# CY8C5888LTI_LP097 register map
File version: 0.1
Registers are 8-bit, read-write, no defined reset value unless marked. A register's access mark holds for its fields unless they carry their own. Offsets are from the block's base; [hi:lo] are bit positions; 'fields as' and 'values as' point back to an identical list.

## PWM_1
Base 0x00000000
0x40006524 PWM_1_COMPARE_Reg 16-bit — UDB.D0 - Assigned Compare Value
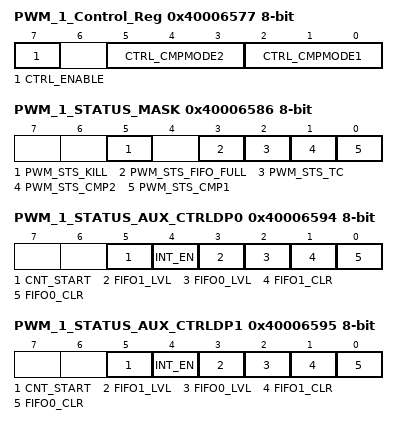
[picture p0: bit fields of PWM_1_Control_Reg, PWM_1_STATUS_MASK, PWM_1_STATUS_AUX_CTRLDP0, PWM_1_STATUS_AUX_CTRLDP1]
0x40006577 PWM_1_Control_Reg — UDB Control Register - Assigned Control Register Value
  [7] CTRL_ENABLE — Enable the PWM
  [5:3] CTRL_CMPMODE2 — Compare mode 2
  [2:0] CTRL_CMPMODE1 — Compare mode 1
0x40006586 PWM_1_STATUS_MASK — UDB Status bits Interrupt Mask Enable Register
  [5] PWM_STS_KILL ro — Enables the Interrupt on Kill
  [3] PWM_STS_FIFO_FULL ro — FIFO Full Status Mask
  [2] PWM_STS_TC ro — Enables the Interrupt on Terminal Count
  [1] PWM_STS_CMP2 ro — Enables the Interrupt on Compare 2
  [0] PWM_STS_CMP1 ro — Enables the Interrupt on Compare 1
0x40006594 PWM_1_STATUS_AUX_CTRLDP0 — UDB Auxilliary Control Register
  [5] CNT_START — FIFO0 clear
    0=E_CNT_START0 (Disable counter); 1=E_CNT_START1 (Enable counter)
  [4] INT_EN
    0=E_INT_EN0 (Interrupt disabled); 1=E_INT_EN1 (Interrupt enabled)
  [3] FIFO1_LVL — FIFO level
    0=E_FIFO_LVL_0 (FIFO LVL: input mode: FIFO not full; output mode: FIFO not empty); 1=E_FIFO_LVL_1 (FIFO LVL: input mode: FIFO at least 1/2 empty; output mode: FIFO at least 1/2 full)
  [2] FIFO0_LVL — FIFO level
    values as FIFO1_LVL
  [1] FIFO1_CLR — FIFO1 clear
    0=E_FIFO_CLR_0 (Normal FIFO operation); 1=E_FIFO_CLR_1 (Clear FIFO state)
  [0] FIFO0_CLR — FIFO0 clear
    values as FIFO1_CLR
0x40006595 PWM_1_STATUS_AUX_CTRLDP1 — UDB Auxilliary Control Register
  fields as PWM_1_STATUS_AUX_CTRLDP0

## Control_Reg_ServoSelect
Base 0x00000000
0x40006476 Control_Reg_ServoSelect_CONTROL_REG

## Control_Reg_ServoTrigger
Base 0x00000000
0x40006576 Control_Reg_ServoTrigger_CONTROL_REG

## Control_Reg_US
Base 0x00000000
0x40006579 Control_Reg_US_CONTROL_REG

## PWM_Trigger
Base 0x00000000
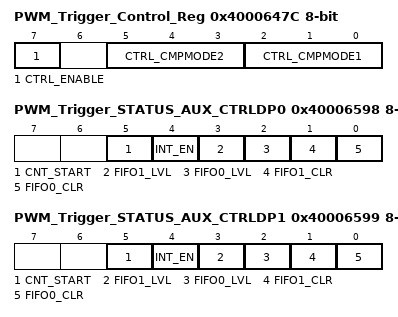
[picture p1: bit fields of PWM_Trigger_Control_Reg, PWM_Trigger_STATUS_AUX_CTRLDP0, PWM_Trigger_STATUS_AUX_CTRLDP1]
0x4000647C PWM_Trigger_Control_Reg — UDB Control Register - Assigned Control Register Value
  [7] CTRL_ENABLE — Enable the PWM
  [5:3] CTRL_CMPMODE2 — Compare mode 2
  [2:0] CTRL_CMPMODE1 — Compare mode 1
0x40006528 PWM_Trigger_COMPARE_Reg 16-bit — UDB.D0 - Assigned Compare Value
0x40006598 PWM_Trigger_STATUS_AUX_CTRLDP0 — UDB Auxilliary Control Register
  [5] CNT_START — FIFO0 clear
    0=E_CNT_START0 (Disable counter); 1=E_CNT_START1 (Enable counter)
  [4] INT_EN
    0=E_INT_EN0 (Interrupt disabled); 1=E_INT_EN1 (Interrupt enabled)
  [3] FIFO1_LVL — FIFO level
    0=E_FIFO_LVL_0 (FIFO LVL: input mode: FIFO not full; output mode: FIFO not empty); 1=E_FIFO_LVL_1 (FIFO LVL: input mode: FIFO at least 1/2 empty; output mode: FIFO at least 1/2 full)
  [2] FIFO0_LVL — FIFO level
    values as FIFO1_LVL
  [1] FIFO1_CLR — FIFO1 clear
    0=E_FIFO_CLR_0 (Normal FIFO operation); 1=E_FIFO_CLR_1 (Clear FIFO state)
  [0] FIFO0_CLR — FIFO0 clear
    values as FIFO1_CLR
0x40006599 PWM_Trigger_STATUS_AUX_CTRLDP1 — UDB Auxilliary Control Register
  fields as PWM_Trigger_STATUS_AUX_CTRLDP0

## UART
Base 0x00000000
0x40006444 TX_UART_TX_DATA — TX Data Register
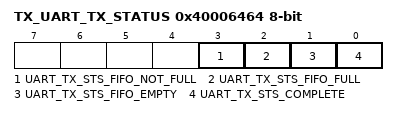
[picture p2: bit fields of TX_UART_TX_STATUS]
0x40006464 TX_UART_TX_STATUS — TX status register
  [3] UART_TX_STS_FIFO_NOT_FULL ro, [2] UART_TX_STS_FIFO_FULL ro, [1] UART_TX_STS_FIFO_EMPTY ro, [0] UART_TX_STS_COMPLETE ro

## Timer_Echo
Base 0x00000000
0x4000640B Timer_Echo_COUNTER 16-bit — UDB.A0 - Current Down Counter Value
0x4000642B Timer_Echo_PERIOD 16-bit — UDB.D0 - Assigned Period
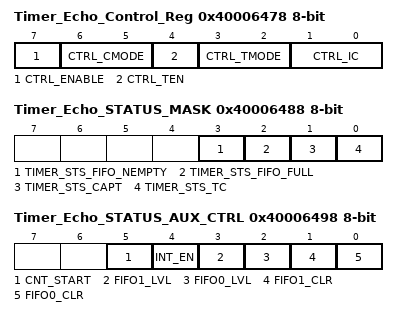
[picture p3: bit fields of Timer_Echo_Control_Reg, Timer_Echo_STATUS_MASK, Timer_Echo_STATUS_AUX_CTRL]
0x40006478 Timer_Echo_Control_Reg — UDB Control Register - Assigned Control Register Value
  [7] CTRL_ENABLE — Enable the Timer
  [6:5] CTRL_CMODE — Capture Mode
  [4] CTRL_TEN — Trigger Enable Bit
  [3:2] CTRL_TMODE — Trigger Mode
  [1:0] CTRL_IC — Interrupt Count
0x40006488 Timer_Echo_STATUS_MASK — UDB Status bits Interrupt Mask Enable Register
  [3] TIMER_STS_FIFO_NEMPTY ro — FIFO Empty status
  [2] TIMER_STS_FIFO_FULL ro — FIFO Full Status
  [1] TIMER_STS_CAPT ro — Enables the Interrupt on Capture
  [0] TIMER_STS_TC ro — Enables the Interrupt on TC
0x40006498 Timer_Echo_STATUS_AUX_CTRL — UDB Auxilliary Control Register
  [5] CNT_START — FIFO0 clear
    0=E_CNT_START0 (Disable counter); 1=E_CNT_START1 (Enable counter)
  [4] INT_EN
    0=E_INT_EN0 (Interrupt disabled); 1=E_INT_EN1 (Interrupt enabled)
  [3] FIFO1_LVL — FIFO level
    0=E_FIFO_LVL_0 (FIFO LVL: input mode: FIFO not full; output mode: FIFO not empty); 1=E_FIFO_LVL_1 (FIFO LVL: input mode: FIFO at least 1/2 empty; output mode: FIFO at least 1/2 full)
  [2] FIFO0_LVL — FIFO level
    values as FIFO1_LVL
  [1] FIFO1_CLR — FIFO1 clear
    0=E_FIFO_CLR_0 (Normal FIFO operation); 1=E_FIFO_CLR_1 (Clear FIFO state)
  [0] FIFO0_CLR — FIFO0 clear
    values as FIFO1_CLR
